# RK3399-AP register map
File version: 1
CPU: CA7 r0p1, little endian, MPU, FPU, I-cache, D-cache, VTOR, 4 interrupt priority bits, 0 interrupts
Registers are 32-bit, read-write, reset 0x0 unless marked. A register's access mark holds for its fields unless they carry their own. Offsets are from the block's base; [hi:lo] are bit positions; {n}, {i} and the like mark numbered series.

## PI0 (part 1 of 2)
Base 0xFFA80800
Same registers: PI1 0xFFA88800
0x00 PI_REG_0 access not given — DDR PHY Independent Register 0
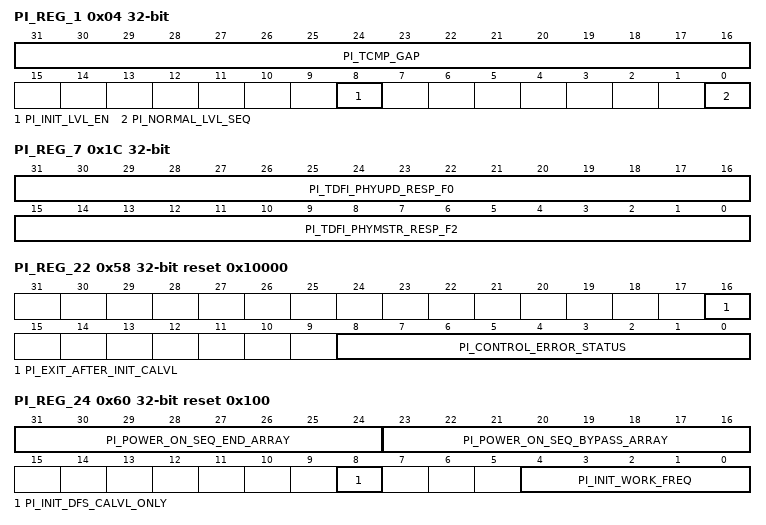
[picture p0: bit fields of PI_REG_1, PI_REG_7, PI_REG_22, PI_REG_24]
0x04 PI_REG_1 — DDR PHY Independent Register 1
  [31:16] PI_TCMP_GAP — Indicates DRAM timing in DFI clock cycles. Specifies the minimum gap between two commands. Used for guarding the timing from the last command of DDR controller and the first command of PI when DDR controller passes the control of the DFI bus to the PI.
  [8] PI_INIT_LVL_EN — Enables the initial leveling sequence after PI initialization procedure. Set to 1 to enable.
  [0] PI_NORMAL_LVL_SEQ — Enables the PI strategy that PI must finish all the pending leveling before it releases the DFI bus.
0x08 PI_REG_2 — DDR PHY Independent Register 2
  [31:0] PI_TDFI_PHYMSTR_MAX_F0 — Defines the DFI tPHYMSTR_MAX timing parameter (in DFI clocks), the maximum cycles that dfi_phymstr_req following the assertion of dfi_phymstr_ack can be asserted. If programmed to a non-zero, a timing violation causes an interrupt and bit0 set in the PI_REG_22.pi_control_error_status parameter. The suffix f0 of the parameter name is omitted when in non-DFS mode.
0x0C PI_REG_3 — DDR PHY Independent Register 3
  [15:0] PI_TDFI_PHYMSTR_RESP_F0 — Defines the DFI tPHYMSTR_RESP timing parameter (in DFI clocks), the maximum cycles between a dfi_phymstr_req assertion and a dfi_phymstr_ack assertion. If programmed to a non-zero, a timing violation causes an interrupt and bit1 set in the PI_REG_22.pi_control_error_status parameter. The suffix f0 of the parameter name is omitted when in non-DFS mode.
0x10 PI_REG_4 — DDR PHY Independent Register 4
  [31:0] PI_TDFI_PHYMSTR_MAX_F1 — Defines the DFI tPHYMSTR_MAX timing parameter (in DFI clocks), the maximum cycles that dfi_phymstr_req following the assertion of dfi_phymstr_ack can be asserted. If programmed to a non-zero, a timing violation causes an interrupt and bit0 set in the PI_REG_22.pi_control_error_status parameter. The suffix f1 of the parameter name is omitted when in non-DFS mode.
0x14 PI_REG_5 — DDR PHY Independent Register 5
  [15:0] PI_TDFI_PHYMSTR_RESP_F1 — Defines the DFI tPHYMSTR_RESP timing parameter (in DFI clocks), the maximum cycles between a dfi_phymstr_req assertion and a dfi_phymstr_ack assertion. If programmed to a non-zero, a timing violation causes an interrupt and bit1 set in the PI_REG_22.pi_control_error_status parameter. The suffix f1 of the parameter name is omitted when in non-DFS mode.
0x18 PI_REG_6 — DDR PHY Independent Register 6
  [31:0] PI_TDFI_PHYMSTR_MAX_F2 — Defines the DFI tPHYMSTR_MAX timing parameter (in DFI clocks), the maximum cycles that dfi_phymstr_req following the assertion of dfi_phymstr_ack can be asserted. If programmed to a non-zero, a timing violation causes an interrupt and bit0 set in the PI_REG_22.pi_control_error_status parameter. The suffix f2 of the parameter name is omitted when in non-DFS mode.
0x1C PI_REG_7 — DDR PHY Independent Register 7
  [31:16] PI_TDFI_PHYUPD_RESP_F0 — Defines the DFI tPHYUPD_RESP timing parameter (in DFI clocks), the maximum cycles between a dfi_phyupd_req assertion and a dfi_phyupd_ack assertion. If programmed to a non-zero, a timing violation causes an interrupt and bit8 set in the PI_REG_193.pi_update_error_status parameter and bit8 set in the PI_REG_22.pi_control_error_status parameter. The suffix f0 of the parameter name is omitted when in non-DFS mode.
  [15:0] PI_TDFI_PHYMSTR_RESP_F2 — Defines the DFI tPHYMSTR_RESP timing parameter (in DFI clocks), the maximum cycles between a dfi_phymstr_req assertion and a dfi_phymstr_ack assertion. If programmed to a non-zero, a timing violation causes an interrupt and bit1 set in the PI_REG_22.pi_control_error_status parameter. The suffix f2 of the parameter name is omitted when in non-DFS mode.
{0x0+4i} PI_REG_{i} (i=8..11) — DDR PHY Independent Register {i}
  [31:0] PI_TDFI_PHYUPD_TYPE{i-8}_F0 — Defines the DFI tPHYUPD_TYPE{i-8} timing parameter (in DFI clocks), the maximum cycles that dfi_phyupd_req can assert after dfi_phyupd_ack for dfi_phyupd_type {i-8}. If programmed to a non-zero, a timing violation causes an interrupt and bit{i-4} set in the PI_REG_193.pi_update_error_status parameter and bit{i-4} set in the PI_REG_22.pi_control_error_status parameter. The suffix f0 of the parameter name is omitted when in non-DFS mode.
0x30 PI_REG_12 — DDR PHY Independent Register 12
  [15:0] PI_TDFI_PHYUPD_RESP_F1 — Defines the DFI tPHYUPD_RESP timing parameter (in DFI clocks), the maximum cycles between a dfi_phyupd_req assertion and a dfi_phyupd_ack assertion. If programmed to a non-zero, a timing violation causes an interrupt and bit8 set in the PI_REG_193.pi_update_error_status parameter and bit8 set in the PI_REG_22.pi_control_error_status parameter. The suffix f1 of the parameter name is omitted when in non-DFS mode.
{0x0+4i} PI_REG_{i} (i=13..16) — DDR PHY Independent Register {i}
  [31:0] PI_TDFI_PHYUPD_TYPE{i-13}_F1 — Defines the DFI tPHYUPD_TYPE{i-13} timing parameter (in DFI clocks), the maximum cycles that dfi_phyupd_req can assert after dfi_phyupd_ack for dfi_phyupd_type {i-13}. If programmed to a non-zero, a timing violation causes an interrupt and bit{i-9} set in the PI_REG_193.pi_update_error_status parameter and bit{i-9} set in the PI_REG_22.pi_control_error_status parameter. The suffix f1 of the parameter name is omitted when in non-DFS mode.
0x44 PI_REG_17 — DDR PHY Independent Register 17
  [15:0] PI_TDFI_PHYUPD_RESP_F2 — Defines the DFI tPHYUPD_RESP timing parameter (in DFI clocks), the maximum cycles between a dfi_phyupd_req assertion and a dfi_phyupd_ack assertion. If programmed to a non-zero, a timing violation causes an interrupt and bit8 set in the PI_REG_193.pi_update_error_status parameter and bit8 set in the PI_REG_22.pi_control_error_status parameter. The suffix f2 of the parameter name is omitted when in non-DFS mode.
{0x0+4i} PI_REG_{i} (i=18..21) — DDR PHY Independent Register {i}
  [31:0] PI_TDFI_PHYUPD_TYPE{i-18}_F2 — Defines the DFI tPHYUPD_TYPE{i-18} timing parameter (in DFI clocks), the maximum cycles that dfi_phyupd_req can assert after dfi_phyupd_ack for dfi_phyupd_type {i-18}. If programmed to a non-zero, a timing violation causes an interrupt and bit{i-14} set in the PI_REG_193.pi_update_error_status parameter and bit{i-14} set in the PI_REG_22.pi_control_error_status parameter. The suffix f2 of the parameter name is omitted when in non-DFS mode.
0x58 PI_REG_22 reset 0x10000 — DDR PHY Independent Register 22
  [16] PI_EXIT_AFTER_INIT_CALVL — Releases the DFI bus after complete initialization CA training and requests DFI bus again for the remaining initialization training. The DFI bus release is for the controller to issue MRW/ZQ after the PI completes initialization CA leveling, based on the JEDEC protocol requirement.
  [8:0] PI_CONTROL_ERROR_STATUS — Identifies the source of any pi_control phyupd_req/ phylvl_req_cs_n errors. Value of 1 indicates a timing violation of the associated timing parameter Bit 8: pi_control triggered phyupd_resp_error. Bit 7: pi_control triggered phyupd_type3_error. Bit 6: pi_control triggered phyupd_type2_error. Bit 5: pi_control triggered phyupd_type1_error. Bit 4: pi_control triggered phyupd_type0_error. Bit 3: phylvl_resp_error. Bit 2: phylvl_max_error. Bit 1: phymstr_resp_error. Bit 0: phymstr_max_error.
0x5C PI_REG_23 — DDR PHY Independent Register 23
  [31:0] PI_FREQ_MAP — User indicates all the supported working frequencies. Each bit represents one supported frequency.
0x60 PI_REG_24 reset 0x100 — DDR PHY Independent Register 24
  [31:24] PI_POWER_ON_SEQ_END_ARRAY — Indicates the step that is the last step of the power-on sequence.
  [23:16] PI_POWER_ON_SEQ_BYPASS_ARRAY — Indicates the bypassed steps of power on sequence.
  [8] PI_INIT_DFS_CALVL_ONLY — Enables the initial leveling sequence loop that only CA training executes DFS.
  [4:0] PI_INIT_WORK_FREQ — Indicates the initial work frequency after initialization and initial leveling sequence.
0x64 PI_REG_25 — DDR PHY Independent Register 25
  [29:0] PI_SEQ1_PAT — Indicates user-defined power-on sequence 1.
0x68 PI_REG_26 — DDR PHY Independent Register 26
  [29:0] PI_SEQ1_PAT_MASK — Indicates user-defined command mask for power-on sequence 1.
0x6C PI_REG_27 — DDR PHY Independent Register 27
  [29:0] PI_SEQ2_PAT — Indicates user-defined power-on sequence 2.
0x70 PI_REG_28 — DDR PHY Independent Register 28
  [29:0] PI_SEQ2_PAT_MASK — Indicates user-defined command mask for power-on sequence 2.
0x74 PI_REG_29 — DDR PHY Independent Register 29
  [29:0] PI_SEQ3_PAT — Indicates user-defined power-on sequence 3.
0x78 PI_REG_30 — DDR PHY Independent Register 30
  [29:0] PI_SEQ3_PAT_MASK — Indicates user-defined command mask for power-on sequence 3.
0x7C PI_REG_31 — DDR PHY Independent Register 31
  [29:0] PI_SEQ4_PAT — Indicates user-defined power-on sequence 4.
0x80 PI_REG_32 — DDR PHY Independent Register 32
  [29:0] PI_SEQ4_PAT_MASK — Indicates user-defined command mask for power-on sequence 4.
0x84 PI_REG_33 — DDR PHY Independent Register 33
  [29:0] PI_SEQ5_PAT — Indicates user-defined power-on sequence 5.
0x88 PI_REG_34 — DDR PHY Independent Register 34
  [29:0] PI_SEQ5_PAT_MASK — Indicates user-defined command mask for power-on sequence 5.
0x8C PI_REG_35 — DDR PHY Independent Register 35
  [29:0] PI_SEQ6_PAT — Indicates user-defined power-on sequence 6.
0x90 PI_REG_36 — DDR PHY Independent Register 36
  [29:0] PI_SEQ6_PAT_MASK — Indicates user-defined command mask for power-on sequence 6.
0x94 PI_REG_37 — DDR PHY Independent Register 37
  [29:0] PI_SEQ7_PAT — Indicates user-defined power-on sequence 7.
0x98 PI_REG_38 — DDR PHY Independent Register 38
  [29:0] PI_SEQ7_PAT_MASK — Indicates user-defined command mask for power-on sequence 7.
0x9C PI_REG_39 — DDR PHY Independent Register 39
  [29:0] PI_SEQ8_PAT — Indicates user-defined power-on sequence 8.
0xA0 PI_REG_40 — DDR PHY Independent Register 40
  [29:0] PI_SEQ8_PAT_MASK — Indicates user-defined command mask for power-on sequence 8.
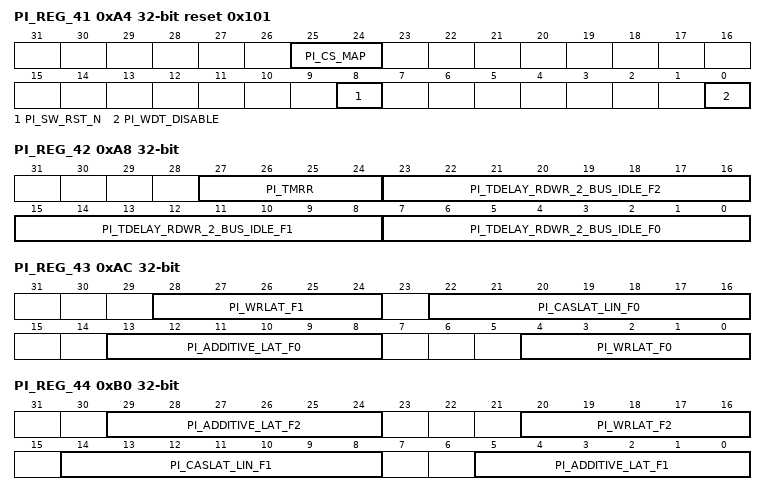
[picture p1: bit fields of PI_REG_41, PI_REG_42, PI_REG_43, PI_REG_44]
0xA4 PI_REG_41 reset 0x101 — DDR PHY Independent Register 41
  [25:24] PI_CS_MAP — Defines the chip selects that are active.
  [8] PI_SW_RST_N — Indicates user request to reset the whole system except parameter DFFs. Set 0 to reset, set to 1 to release.
  [0] PI_WDT_DISABLE — Disables the watchdog caused by phymstr_req/phylvl_req_cs_n response error. Set 1 to disable.
0xA8 PI_REG_42 — DDR PHY Independent Register 42
  [27:24] PI_TMRR — Indicates DRAM TMRR value in cycles.
  [23:16] PI_TDELAY_RDWR_2_BUS_IDLE_F2 — Indicates the delay from read or write to bus idle. Recommended setting is delay time from read command that issued to the last read data received. The suffix "_f2" of the parameter name is omitted when in non-DFS mode.
  [15:8] PI_TDELAY_RDWR_2_BUS_IDLE_F1 — Indicates the delay from read or write to bus idle. Recommended setting is delay time from read command that issued to the last read data received. The suffix "_f1" of the parameter name is omitted when in non-DFS mode.
  [7:0] PI_TDELAY_RDWR_2_BUS_IDLE_F0 — Indicates the delay from read or write to bus idle. Recommended setting is delay time from read command that issued to the last read data received. The suffix "_f0" of the parameter name is omitted when in non-DFS mode.
0xAC PI_REG_43 — DDR PHY Independent Register 43
  [28:24] PI_WRLAT_F1 — Indicates DRAM WRLAT value in cycles. The suffix "_f1" of the parameter name is omitted when in non-DFS mode.
  [22:16] PI_CASLAT_LIN_F0 — Sets latency from read command send to data receive from/to controller. Bit0 is half-cycle increment and the upper bits define memory CAS latency for the controller. The suffix "_f0" of the parameter name is omitted when in non-DFS mode.
  [13:8] PI_ADDITIVE_LAT_F0 — Indicates DRAM additive latency value in cycles. The suffix "_f0" of the parameter name is omitted when in non-DFS mode.
  [4:0] PI_WRLAT_F0 — Indicates DRAM WRLAT value in cycles. The suffix "_f0" of the parameter name is omitted when in non-DFS mode.
0xB0 PI_REG_44 — DDR PHY Independent Register 44
  [29:24] PI_ADDITIVE_LAT_F2 — Indicates DRAM additive latency value in cycles. The suffix "_f2" of the parameter name is omitted when in non-DFS mode.
  [20:16] PI_WRLAT_F2 — Indicates DRAM WRLAT value in cycles. The suffix "_f2" of the parameter name is omitted when in non-DFS mode.
  [14:8] PI_CASLAT_LIN_F1 — Sets latency from read command send to data receive from/to controller. Bit0 is half-cycle increment and the upper bits define memory CAS latency for the controller. The suffix "_f1" of the parameter name is omitted when in non-DFS mode.
  [5:0] PI_ADDITIVE_LAT_F1 — Indicates DRAM additive latency value in cycles. The suffix "_f1" of the parameter name is omitted when in non-DFS mode.
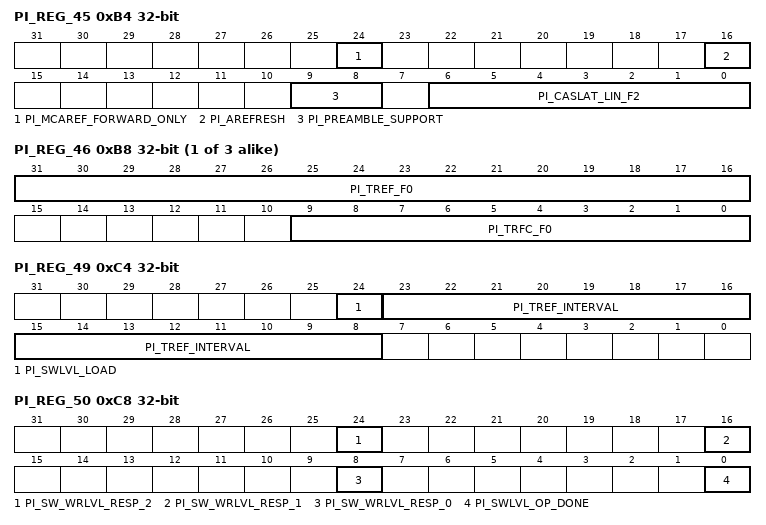
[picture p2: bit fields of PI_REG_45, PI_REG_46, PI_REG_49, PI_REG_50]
0xB4 PI_REG_45 access per field — DDR PHY Independent Register 45
  [24] PI_MCAREF_FORWARD_ONLY rw — Pass mc auto refresh command to DRAM device, not generate auto-refresh by PI. It is recommended to set to 1.
  [16] PI_AREFRESH wo — Initiates auto-refresh at the end of the current burst boundary. Set to 1 to trigger.
  [9:8] PI_PREAMBLE_SUPPORT rw — Indicates selection of one or two-cycle preamble for read and write burst transfers.
  [6:0] PI_CASLAT_LIN_F2 rw — Sets latency from read command send to data receive from/to controller. Bit0 is half-cycle increment and the upper bits define memory CAS latency for the controller. The suffix "_f2" of the parameter name is omitted when in non-DFS mode.
{0x0+4i} PI_REG_{i} (i=46..48) — DDR PHY Independent Register {i}
  [31:16] PI_TREF_F{i-46} — Indicates DRAM TREF value in cycles. The suffix "_f{i-46}" of the parameter name is omitted when in non-DFS mode.
  [9:0] PI_TRFC_F{i-46} — Indicates DRAM TRFC value in cycles. The suffix "_f{i-46}" of the parameter name is omitted when in non-DFS mode.
0xC4 PI_REG_49 access per field — DDR PHY Independent Register 49
  [24] PI_SWLVL_LOAD wo — Indicates user request to load delays and execute software leveling. Set to 1 to trigger.
  [23:8] PI_TREF_INTERVAL rw — Defines the cycles between refreshes to different chip selects.
0xC8 PI_REG_50 ro — DDR PHY Independent Register 50
  [24] PI_SW_WRLVL_RESP_2 — Indicates write leveling response for data slice 2.
  [16] PI_SW_WRLVL_RESP_1 — Indicates write leveling response for data slice 1.
  [8] PI_SW_WRLVL_RESP_0 — Indicates write leveling response for data slice 0.
  [0] PI_SWLVL_OP_DONE — Indicates signals that software leveling is currently in progress. Value of 1 indicates operation complete.
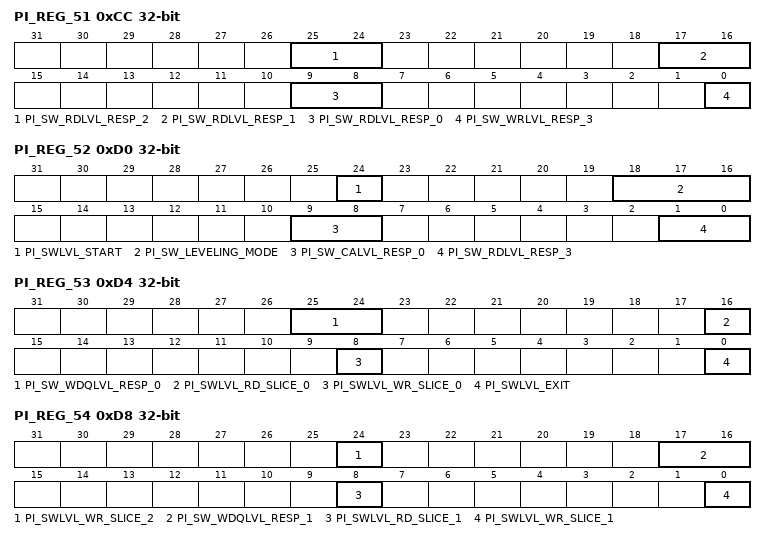
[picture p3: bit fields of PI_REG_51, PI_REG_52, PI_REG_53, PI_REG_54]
0xCC PI_REG_51 ro — DDR PHY Independent Register 51
  [25:24] PI_SW_RDLVL_RESP_2 — Indicates read leveling response for data slice 2.
  [17:16] PI_SW_RDLVL_RESP_1 — Indicates read leveling response for data slice 1.
  [9:8] PI_SW_RDLVL_RESP_0 — Indicates read leveling response for data slice 0.
  [0] PI_SW_WRLVL_RESP_3 — Indicates write leveling response for data slice 3.
0xD0 PI_REG_52 access per field — DDR PHY Independent Register 52
  [24] PI_SWLVL_START wo — Indicates user request to initiate software leveling of type in the PI_REG_52.pi_sw_leveling_mode parameter. Set to 1 to trigger.
  [18:16] PI_SW_LEVELING_MODE rw — Defines the leveling operation for software leveling. Set to 3\'b001 for write leveling, set to 3\'b010 for read data eye training, set to 3\'b011 for read gate training, set to 3\'b100 for ca training, set to 3\'b101 for WDQ training.
  [9:8] PI_SW_CALVL_RESP_0 ro — Indicates CA leveling response for data slice 0.
  [1:0] PI_SW_RDLVL_RESP_3 ro — Indicates read leveling response for data slice 3.
0xD4 PI_REG_53 access per field — DDR PHY Independent Register 53
  [25:24] PI_SW_WDQLVL_RESP_0 ro — Indicates WDQ leveling response for data slice 0.
  [16] PI_SWLVL_RD_SLICE_0 wo — Indicates software leveling read command in WDQ training for data slice 0.
  [8] PI_SWLVL_WR_SLICE_0 wo — Indicates software leveling write command in WDQ training for data slice 0.
  [0] PI_SWLVL_EXIT wo — Indicates user request to exit software leveling. Set to 1 to exit.
0xD8 PI_REG_54 access per field — DDR PHY Independent Register 54
  [24] PI_SWLVL_WR_SLICE_2 wo — Indicates software leveling write command in WDQ training for data slice 2.
  [17:16] PI_SW_WDQLVL_RESP_1 ro — Indicates WDQ leveling response for data slice 1.
  [8] PI_SWLVL_RD_SLICE_1 wo — Indicates software leveling read command in WDQ training for data slice 1.
  [0] PI_SWLVL_WR_SLICE_1 wo — Indicates software leveling write command in WDQ training for data slice 1.
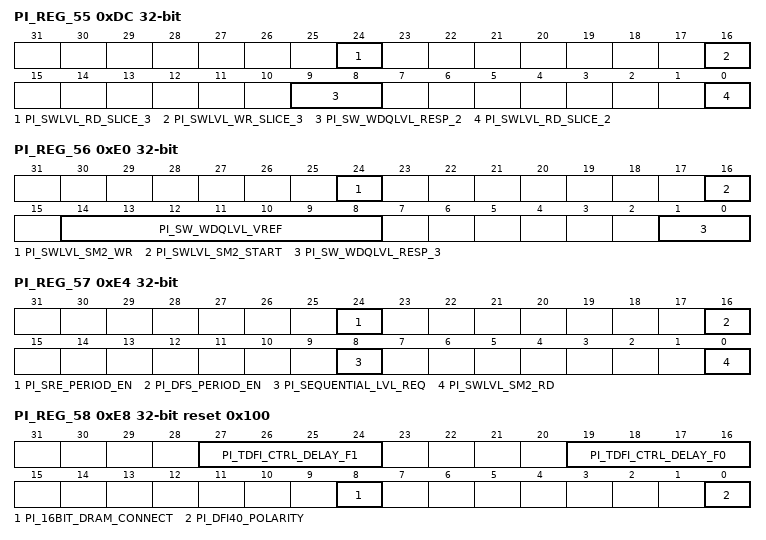
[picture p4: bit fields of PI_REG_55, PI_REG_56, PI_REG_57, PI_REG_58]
0xDC PI_REG_55 access per field — DDR PHY Independent Register 55
  [24] PI_SWLVL_RD_SLICE_3 wo — Indicates software leveling read command in WDQ training for data slice 3.
  [16] PI_SWLVL_WR_SLICE_3 wo — Indicates software leveling write command in WDQ training for data slice 3.
  [9:8] PI_SW_WDQLVL_RESP_2 ro — Indicates WDQ leveling response for data slice 2.
  [0] PI_SWLVL_RD_SLICE_2 wo — Indicates software leveling read command in WDQ training for data slice 2.
0xE0 PI_REG_56 access per field — DDR PHY Independent Register 56
  [24] PI_SWLVL_SM2_WR wo — Indicates software leveling write command for stage 2.
  [16] PI_SWLVL_SM2_START wo — Indicates software leveling start command for stage 2.
  [14:8] PI_SW_WDQLVL_VREF rw — Indicates user-defined WDQ vref value in software leveling debug mode.
  [1:0] PI_SW_WDQLVL_RESP_3 ro — Indicates WDQ leveling response for data slice 3.
0xE4 PI_REG_57 access per field — DDR PHY Independent Register 57
  [24] PI_SRE_PERIOD_EN rw — Enables the selfrefresh exit-triggered periodic leveling.
  [16] PI_DFS_PERIOD_EN rw — Enables the DFS-triggered periodic leveling.
  [8] PI_SEQUENTIAL_LVL_REQ wo — Indicates user request to initiate the leveling sequence. Set to 1 to trigger.
  [0] PI_SWLVL_SM2_RD wo — Indicates software leveling read command for stage 2.
0xE8 PI_REG_58 reset 0x100 — DDR PHY Independent Register 58
  [27:24] PI_TDFI_CTRL_DELAY_F1 — Defines the DFI tCTRL_DELAY timing parameter (in DFI clocks), the delay between a DFI command change and a memory command. The suffix "_f1" of the parameter name is omitted when in non-DFS mode.
  [19:16] PI_TDFI_CTRL_DELAY_F0 — Defines the DFI tCTRL_DELAY timing parameter (in DFI clocks), the delay between a DFI command change and a memory command. The suffix "_f0" of the parameter name is omitted when in non-DFS mode.
  [8] PI_16BIT_DRAM_CONNECT — Enables 16/32bit DRAM configuration. 1\'b1: 16-bit DRAM 1\'b0: 32-bit DRAM
  [0] PI_DFI40_POLARITY — Control polarity of dfi_wrdata_cs_n/dfi_rddata_cs_n generated by PI. It need match with that of controller\'s polarity. If controller\'s dfi_wrdata_cs_n/ dfi_rddata_cs_n is high active, pi_dfi40_polarity should be 1, otherwise, it should be 0. If LPDDR4 connected, it is recommended to set to 1 to match with latest DFI 4.0 protocol.
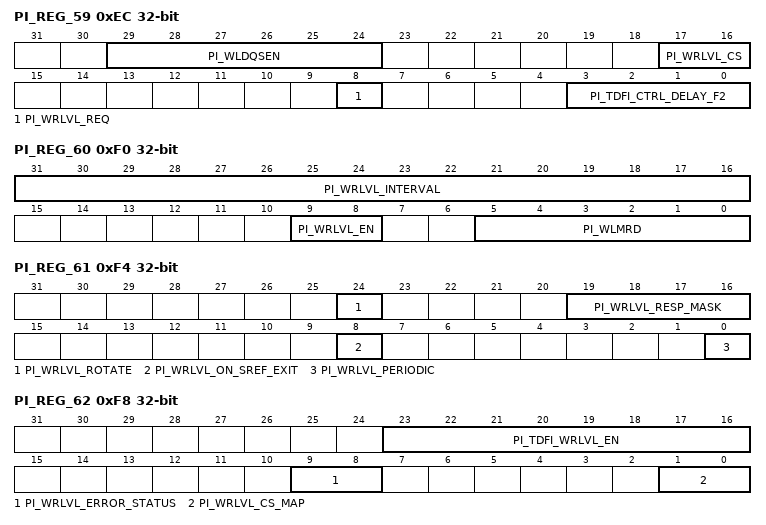
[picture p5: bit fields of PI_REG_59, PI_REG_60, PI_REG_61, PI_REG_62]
0xEC PI_REG_59 access per field — DDR PHY Independent Register 59
  [29:24] PI_WLDQSEN rw — Indicates delay from the issuing MRS to the first DQS strobe for write leveling.
  [17:16] PI_WRLVL_CS rw — Specifies the target chip select for the write leveling operation that is initiated through the PI_REG_59.pi_wrlvl_req parameter.
  [8] PI_WRLVL_REQ wo — Indicates user request to initiate write leveling. Set to 1 to trigger.
  [3:0] PI_TDFI_CTRL_DELAY_F2 rw — Defines the DFI tCTRL_DELAY timing parameter (in DFI clocks), the delay between a DFI command change and a memory command. The suffix "_f2" of the parameter name is omitted when in non-DFS mode.
0xF0 PI_REG_60 — DDR PHY Independent Register 60
  [31:16] PI_WRLVL_INTERVAL — Indicates the number of long count sequences that are counted between automatic write leveling commands.
  [9:8] PI_WRLVL_EN — Enables the PI write leveling module. Bit1 represents the support when non-initialization. Bit0 represents the support when initialization. Set to 1 to enable.
  [5:0] PI_WLMRD — Indicates delay from the issuing MRS to the first write leveling strobe.
0xF4 PI_REG_61 — DDR PHY Independent Register 61
  [24] PI_WRLVL_ROTATE — Enables rotational chip select for interval write leveling. Set to 1 for rotating chip select.
  [19:16] PI_WRLVL_RESP_MASK — Indicates mask for the dfi_wrlvl_resp signal during write leveling.
  [8] PI_WRLVL_ON_SREF_EXIT — Enables automatic write leveling on a self-refresh exit. Set to 1 to enable.
  [0] PI_WRLVL_PERIODIC — Enables the use of the dfi_lvl_periodic signal during write leveling. Set to 1 to enable.
0xF8 PI_REG_62 access per field — DDR PHY Independent Register 62
  [23:16] PI_TDFI_WRLVL_EN rw — Defines the DFI tWRLVL_EN timing parameter (in DFI clocks), the minimum cycles from a dfi_wrlvl_en assertion to the first dfi_wrlvl_strobe assertion.
  [9:8] PI_WRLVL_ERROR_STATUS ro — Holds the error that is associated with the write level error interrupt. Bit0 set indicates a PI_REG_65.pi_tdfi_wrlvl_max parameter violation and bit1 set indicates a PI_REG_64.pi_tdfi_wrlvl_resp parameter violation.
  [1:0] PI_WRLVL_CS_MAP rw — Defines the chip select map for write leveling operations. Bit0 controls cs0, bit1 controls cs1. Set each bit to 1 to enable chip for write leveling.
0xFC PI_REG_63 — DDR PHY Independent Register 63
  [9:0] PI_TDFI_WRLVL_WW — Defines the DFI tWRLVL_WW timing parameter (in DFI clocks), the minimum cycles between dfi_wrlvl_strobe assertions.
0x100 PI_REG_64 — DDR PHY Independent Register 64
  [31:0] PI_TDFI_WRLVL_RESP — Defines the DFI tWRLVL_RESP timing parameter (in DFI clocks), the maximum cycles between a dfi_wrlvl_req assertion and a dfi_wrlvl_en assertion.
0x104 PI_REG_65 — DDR PHY Independent Register 65
  [31:0] PI_TDFI_WRLVL_MAX — Defines the DFI tWRLVL_MAX timing parameter (in DFI clocks), the maximum cycles between a dfi_wrlvl_en assertion and a valid dfi_wrlvl_resp.
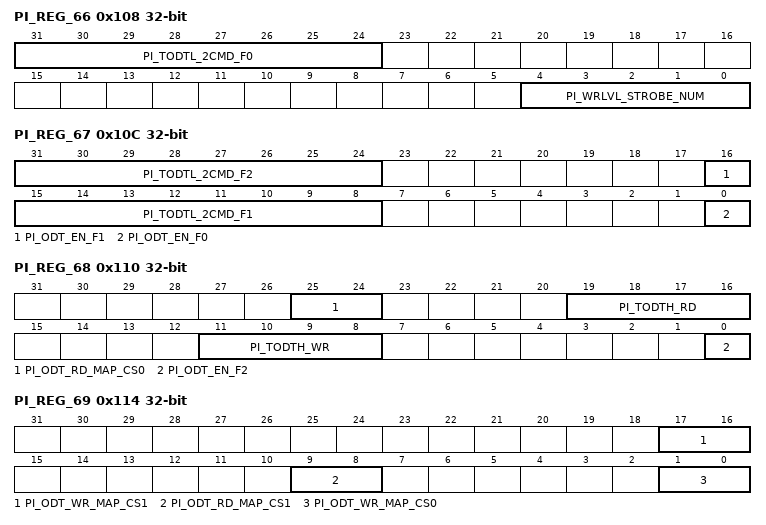
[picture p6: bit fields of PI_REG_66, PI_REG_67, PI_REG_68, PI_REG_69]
0x108 PI_REG_66 — DDR PHY Independent Register 66
  [31:24] PI_TODTL_2CMD_F0 — Defines the DRAM delay from an ODT de-assertion to the next non-write, non-read command. The suffix "_f0" of the parameter name is omitted when in non-DFS mode.
  [4:0] PI_WRLVL_STROBE_NUM — Defines the write leveling strobe number in LPDDR4.
0x10C PI_REG_67 — DDR PHY Independent Register 67
  [31:24] PI_TODTL_2CMD_F2 — Defines the DRAM delay from an ODT de-assertion to the next non-write, non-read command. The suffix "_f2" of the parameter name is omitted when in non-DFS mode.
  [16] PI_ODT_EN_F1 — Enables support of DRAM ODT. When enabled, PI asserts and de-asserts ODT output to DRAM as needed. The suffix "_f1" of the parameter name is omitted when in non-DFS mode.
  [15:8] PI_TODTL_2CMD_F1 — Defines the DRAM delay from an ODT de-assertion to the next non-write, non-read command. The suffix "_f1" of the parameter name is omitted when in non-DFS mode.
  [0] PI_ODT_EN_F0 — Enables support of DRAM ODT. When enabled, PI asserts and de-asserts ODT output to DRAM as needed. The suffix "_f0" of the parameter name is omitted when in non-DFS mode.
0x110 PI_REG_68 — DDR PHY Independent Register 68
  [25:24] PI_ODT_RD_MAP_CS0 — Determines the chip(s) that have termination when a read occurs on chip select 0. Set bit X to enable termination on csX when cs0 is performing a read.
  [19:16] PI_TODTH_RD — Defines the DRAM minimum ODT high time after an ODT assertion for a read command.
  [11:8] PI_TODTH_WR — Defines the DRAM minimum ODT high time after an ODT assertion for a write command.
  [0] PI_ODT_EN_F2 — Enables support of DRAM ODT. When enabled, PI asserts and de-asserts ODT output to DRAM as needed. The suffix "_f2" of the parameter name is omitted when in non-DFS mode.
0x114 PI_REG_69 — DDR PHY Independent Register 69
  [17:16] PI_ODT_WR_MAP_CS1 — Determines the chip(s) that have termination when a write occurs on chip select 1. Set bit X to enable termination on csX when cs1 is performing a write.
  [9:8] PI_ODT_RD_MAP_CS1 — Determines the chip(s) that have termination when a read occurs on chip select 1. Set bit X to enable termination on csX when cs1 is performing a read.
  [1:0] PI_ODT_WR_MAP_CS0 — Determines the chip(s) that have termination when a write occurs on chip select 0. Set bit X to enable termination on csX when cs0 is performing a write.
0x118 PI_REG_70 — DDR PHY Independent Register 70
  [24] PI_EN_ODT_ASSERT_EXCEPT_RD — Enables controller to assert ODT at all times except during reads. Assumes a single ODT pin is connected. Set to 1 to enable.
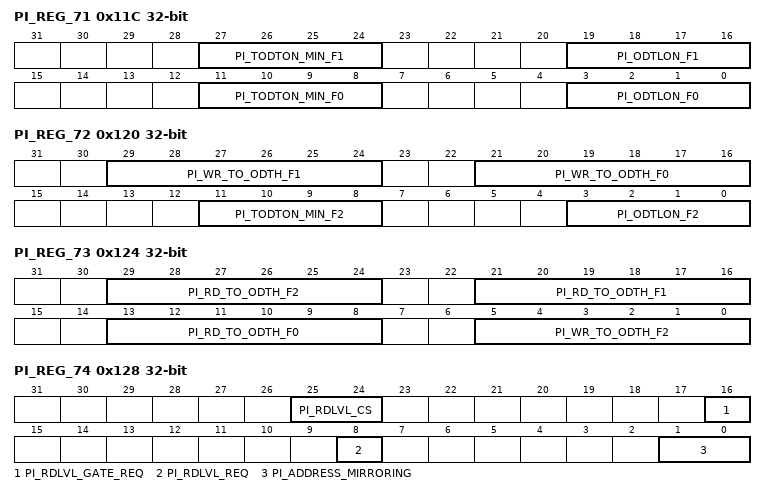
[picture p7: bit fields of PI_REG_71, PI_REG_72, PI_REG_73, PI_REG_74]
0x11C PI_REG_71 — DDR PHY Independent Register 71
  [27:24] PI_TODTON_MIN_F1 — Defines the point in time when the device termination circuit leaves High-Z and ODT resistance begins to turn on. The suffix "_f1" of the parameter name is omitted when in non-DFS mode.
  [19:16] PI_ODTLON_F1 — Defines the latency from a CAS-2 command to the tODTon reference. The suffix "_f1" of the parameter name is omitted when in non-DFS mode.
  [11:8] PI_TODTON_MIN_F0 — Defines the point in time when the device termination circuit leaves High-Z and ODT resistance begins to turn on. The suffix "_f0" of the parameter name is omitted when in non-DFS mode.
  [3:0] PI_ODTLON_F0 — Defines the latency from a CAS-2 command to the tODTon reference. The suffix "_f0" of the parameter name is omitted when in non-DFS mode.
0x120 PI_REG_72 — DDR PHY Independent Register 72
  [29:24] PI_WR_TO_ODTH_F1 — Defines the DRAM Write command to ODT set in cycles. The suffix "_f1" of the parameter name is omitted when in non-DFS mode.
  [21:16] PI_WR_TO_ODTH_F0 — Defines the DRAM Write command to ODT set in cycles. The suffix "_f0" of the parameter name is omitted when in non-DFS mode.
  [11:8] PI_TODTON_MIN_F2 — Defines the point in time when the device termination circuit leaves High-Z and ODT resistance begins to turn on. The suffix "_f2" of the parameter name is omitted when in non-DFS mode.
  [3:0] PI_ODTLON_F2 — Defines the latency from a CAS-2 command to the tODTon reference. The suffix "_f2" of the parameter name is omitted when in non-DFS mode.
0x124 PI_REG_73 — DDR PHY Independent Register 73
  [29:24] PI_RD_TO_ODTH_F2 — Defines the DRAM Read command to ODT set in cycles. The suffix "_f2" of the parameter name is omitted when in non-DFS mode.
  [21:16] PI_RD_TO_ODTH_F1 — Defines the DRAM Read command to ODT set in cycles. The suffix "_f1" of the parameter name is omitted when in non-DFS mode.
  [13:8] PI_RD_TO_ODTH_F0 — Defines the DRAM Read command to ODT set in cycles. The suffix "_f0" of the parameter name is omitted when in non-DFS mode.
  [5:0] PI_WR_TO_ODTH_F2 — Defines the DRAM Write command to ODT set in cycles. The suffix "_f2" of the parameter name is omitted when in non-DFS mode.
0x128 PI_REG_74 access per field — DDR PHY Independent Register 74
  [25:24] PI_RDLVL_CS rw — Specifies the target chip select for the data eye training operation that is initiated through the PI_REG_74.pi_rdlvl_req parameter or the gate training operation that is initiated through the PI_REG_74.pi_rdlvl_gate_req parameter.
  [16] PI_RDLVL_GATE_REQ wo — Indicates user request to initiate gate training. Set to 1 to trigger.
  [8] PI_RDLVL_REQ wo — Indicates user request to initiate data eye training. Set to 1 to trigger.
  [1:0] PI_ADDRESS_MIRRORING rw — Indicates the chip selects that support address mirroring. Bit0 controls cs0, bit1 controls cs1. Set each bit to 1 to enable.
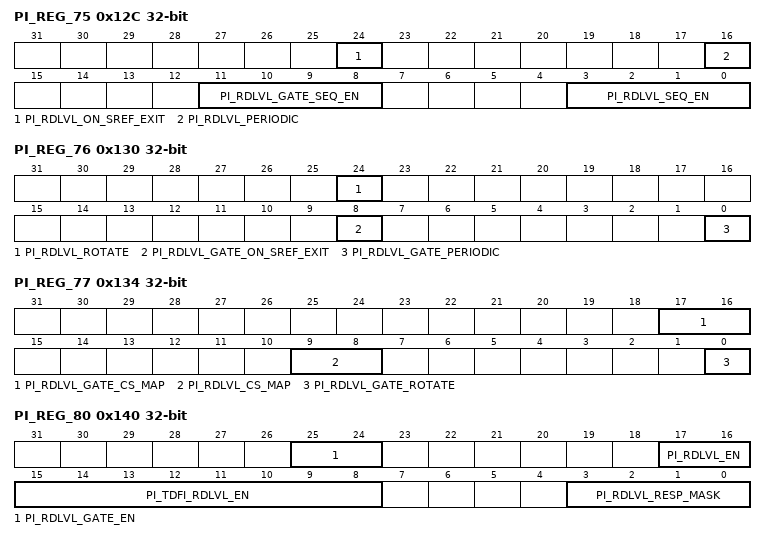
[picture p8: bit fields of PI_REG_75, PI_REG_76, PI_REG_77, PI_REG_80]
0x12C PI_REG_75 — DDR PHY Independent Register 75
  [24] PI_RDLVL_ON_SREF_EXIT — Enables automatic data eye training on a self-refresh exit. Set to 1 to enable.
  [16] PI_RDLVL_PERIODIC — Enables the use of the dfi_lvl_periodic signal during data eye training. Set to 1 to enable.
  [11:8] PI_RDLVL_GATE_SEQ_EN — Specifies the pattern, format and MPR for gate training.
  [3:0] PI_RDLVL_SEQ_EN — Specifies the pattern, format, and MPR for data eye training.
0x130 PI_REG_76 — DDR PHY Independent Register 76
  [24] PI_RDLVL_ROTATE — Enables rotational chip select for interval data eye training. Set to 1 for rotating CS.
  [8] PI_RDLVL_GATE_ON_SREF_EXIT — Enables automatic gate training on a self-refresh exit. Set to 1 to enable.
  [0] PI_RDLVL_GATE_PERIODIC — Enables the use of the dfi_lvl_periodic signal during gate training. Set to 1 to enable.
0x134 PI_REG_77 — DDR PHY Independent Register 77
  [17:16] PI_RDLVL_GATE_CS_MAP — Defines the chip select map for gate training operations. Bit0 controls cs0, bit1 controls cs1. Set each bit to 1 to enable chip for gate training.
  [9:8] PI_RDLVL_CS_MAP — Defines the chip select map for data eye training operations. Bit0 controls cs0, bit1 controls cs1. Set each bit to 1 to enable chip for data eye training.
  [0] PI_RDLVL_GATE_ROTATE — Enables rotational chip select for interval gate training. Set to 1 for rotating CS.
0x138 PI_REG_78 — DDR PHY Independent Register 78
  [9:0] PI_TDFI_RDLVL_RR — Defines the DFI tRDLVL_RR timing parameter (in DFI clocks), the minimum cycles between read commands.
0x13C PI_REG_79 — DDR PHY Independent Register 79
  [31:0] PI_TDFI_RDLVL_RESP — Defines the DFI tRDLVL_RESP timing parameter (in DFI clocks), the maximum cycles between a dfi_rdlvl_req or dfi_rdlvl_gate_req assertion and a dfi_rdlvl_en or dfi_rdlvl_gate_en assertion.
0x140 PI_REG_80 — DDR PHY Independent Register 80
  [25:24] PI_RDLVL_GATE_EN — Enables the PI gate training module. Bit1 represents the support when non-initialization. Bit0 represents the support when initialization. Set to 1 to enable.
  [17:16] PI_RDLVL_EN — Enables the PI data eye training module. Bit1 represents the support when non-initialization. Bit0 represents the support when initialization. Set to 1 to enable.
  [15:8] PI_TDFI_RDLVL_EN — Defines the DFI tRDLVL_EN timing parameter (in DFI clocks), the minimum cycles from a dfi_rdlvl_en or dfi_rdlvl_gate_en assertion to the first read or MRR.
  [3:0] PI_RDLVL_RESP_MASK — Indicates mask for the dfi_rdlvl_resp signal during data eye training.
0x144 PI_REG_81 — DDR PHY Independent Register 81
  [31:0] PI_TDFI_RDLVL_MAX — Defines the DFI tRDLVL_MAX timing parameter (in DFI clocks), the maximum cycles between a dfi_rdlvl_en or dfi_rdlvl_gate_en assertion and a valid dfi_rdlvl_resp.
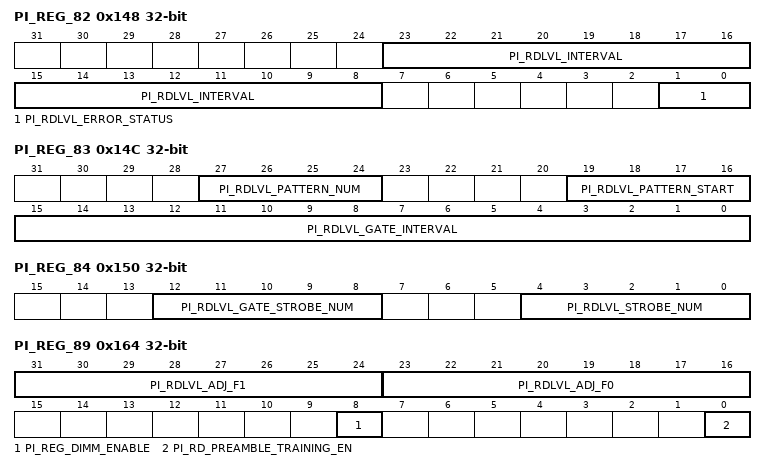
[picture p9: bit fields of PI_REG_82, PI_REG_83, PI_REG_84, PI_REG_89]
0x148 PI_REG_82 access per field — DDR PHY Independent Register 82
  [23:8] PI_RDLVL_INTERVAL rw — Indicates the number of long count sequences that are counted between automatic data eye training commands.
  [1:0] PI_RDLVL_ERROR_STATUS ro — Holds the error that is associated with the data eye training error or gate training error interrupt. The uppermost bit set indicates a PI_REG_79.pi_tdfi_rdlvl_resp parameter violation. The next uppermost bit set indicates a PI_REG_81.pi_tdfi_rdlvl_max parameter violation. Lower bits are reserved.
0x14C PI_REG_83 — DDR PHY Independent Register 83
  [27:24] PI_RDLVL_PATTERN_NUM — Defines the number of patterns that are supported in read leveling.
  [19:16] PI_RDLVL_PATTERN_START — Defines the start pattern in read leveling.
  [15:0] PI_RDLVL_GATE_INTERVAL — The number of long count sequences that are counted between automatic gate training commands.
0x150 PI_REG_84 — DDR PHY Independent Register 84
  [12:8] PI_RDLVL_GATE_STROBE_NUM — Defines the number of back-to-back MPC command in one read process in read gate training.
  [4:0] PI_RDLVL_STROBE_NUM — Defines the number of back to back MPC command in one read process in read eye training.
{0x0+4i} PI_REG_{i} (i=85..88) — DDR PHY Independent Register {i}
  [31:0] PI_LPDDR4_RDLVL_PATTERN_{i-77} — Indicates user-defined LPDDR4 read data pattern {i-77}.
0x164 PI_REG_89 — DDR PHY Independent Register 89
  [31:24] PI_RDLVL_ADJ_F1 — Indicates the adjustment value for PHY read timing. The suffix "_f1" of the parameter name is omitted when in non-DFS mode.
  [23:16] PI_RDLVL_ADJ_F0 — Indicates the adjustment value for PHY read timing. The suffix "_f0" of the parameter name is omitted when in non-DFS mode.
  [8] PI_REG_DIMM_ENABLE — Enables registered DIMM operation. Set to 1 to enable.
  [0] PI_RD_PREAMBLE_TRAINING_EN — Enables read preamble training during data eye training. Set to 1 to enable.
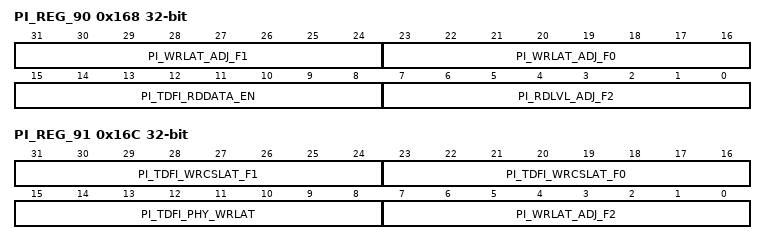
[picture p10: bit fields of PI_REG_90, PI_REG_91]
0x168 PI_REG_90 access per field — DDR PHY Independent Register 90
  [31:24] PI_WRLAT_ADJ_F1 rw — Indicates the adjustment value for PHY write timing. The suffix "_f1" of the parameter name is omitted when in non-DFS mode.
  [23:16] PI_WRLAT_ADJ_F0 rw — Indicates the adjustment value for PHY write timing. The suffix "_f0" of the parameter name is omitted when in non-DFS mode.
  [15:8] PI_TDFI_RDDATA_EN ro — Holds the calculated DFI tRDDATA_EN timing parameter (in DFI PHY clocks), the maximum cycles between a read command and a dfi_rddata_en assertion.
  [7:0] PI_RDLVL_ADJ_F2 rw — Indicates the adjustment value for PHY read timing. The suffix "_f2" of the parameter name is omitted when in non-DFS mode.
0x16C PI_REG_91 access per field — DDR PHY Independent Register 91
  [31:24] PI_TDFI_WRCSLAT_F1 rw — Defines the DFI tPHY_WRCSLAT timing parameter (in DFI PHY clocks), the maximum cycles between a write command and a dfi_wrdata_cs_n assertion. The suffix "_f1" of the parameter name is omitted when in non-DFS mode.
  [23:16] PI_TDFI_WRCSLAT_F0 rw — Defines the DFI tPHY_WRCSLAT timing parameter (in DFI PHY clocks), the maximum cycles between a write command and a dfi_wrdata_cs_n assertion. The suffix "_f0" of the parameter name is omitted when in non-DFS mode.
  [15:8] PI_TDFI_PHY_WRLAT ro — Holds the calculated DFI tPHY_WRLAT timing parameter (in DFI PHY clocks), the maximum cycles between a write command and a dfi_wrdata_en assertion.
  [7:0] PI_WRLAT_ADJ_F2 rw — Indicates the adjustment value for PHY write timing. The suffix "_f2" of the parameter name is omitted when in non-DFS mode.
